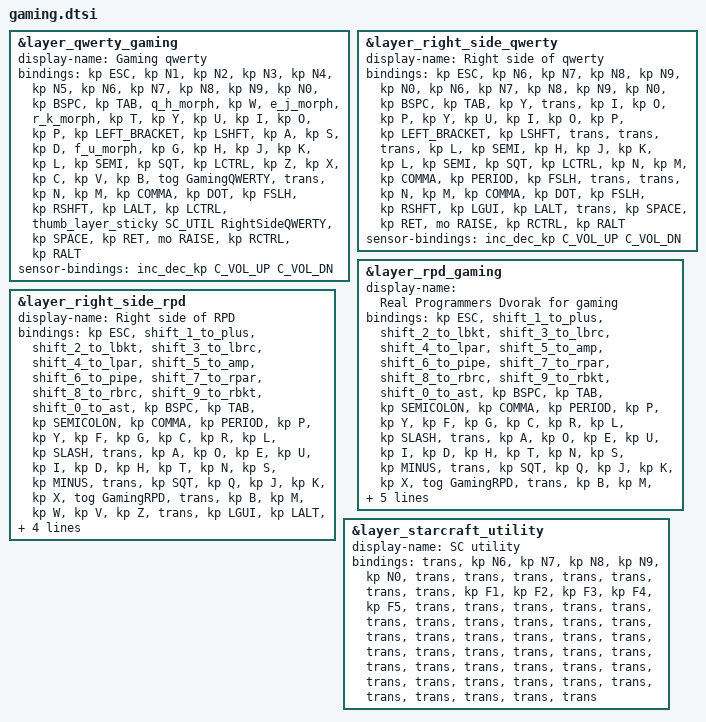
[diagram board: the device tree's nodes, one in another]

        &layer_qwerty_gaming {
            display-name = "Gaming qwerty";
            bindings = <
//    ┌──────┬────────────┬───┬────────────┬────────────┬───────────────────────────────────────────┐                            ┌────────────┬──────┬──────┬───┬───┬──────┐
//    │ esc  │     1      │ 2 │     3      │     4      │                     5                     │                            │     6      │  7   │  8   │ 9 │ 0 │ bspc │
//    ├──────┼────────────┼───┼────────────┼────────────┼───────────────────────────────────────────┤                            ├────────────┼──────┼──────┼───┼───┼──────┤
//    │ tab  │ &q_h_morph │ W │ &e_j_morph │ &r_k_morph │                     T                     │                            │     Y      │  U   │  I   │ O │ P │  [   │
//    ├──────┼────────────┼───┼────────────┼────────────┼───────────────────────────────────────────┤                            ├────────────┼──────┼──────┼───┼───┼──────┤
//    │ lsft │     A      │ S │     D      │ &f_u_morph │                     G                     │                            │     H      │  J   │  K   │ L │ ; │  '   │
//    ├──────┼────────────┼───┼────────────┼────────────┼───────────────────────────────────────────┼──────────────────┐   ┌─────┼────────────┼──────┼──────┼───┼───┼──────┤
//    │ lctl │     Z      │ X │     C      │     V      │                     B                     │ tog GamingQWERTY │   │     │     N      │  M   │  ,   │ . │ / │ rsft │
//    └──────┴────────────┴───┼────────────┼────────────┼───────────────────────────────────────────┼──────────────────┤   ├─────┼────────────┼──────┼──────┼───┴───┴──────┘
//                            │    lgui    │    lalt    │ &thumb_layer_sticky LOWER RightSideQWERTY │       spc        │   │ ent │ mo raltISE │ rctl │ ralt │
//                            └────────────┴────────────┴───────────────────────────────────────────┴──────────────────┘   └─────┴────────────┴──────┴──────┘
  &kp ESC     &kp N1       &kp N2   &kp N3       &kp N4       &kp N5                                                                        &kp N6      &kp N7      &kp N8      &kp N9    &kp N0     &kp BSPC
  &kp TAB     &q_h_morph   &kp W    &e_j_morph   &r_k_morph   &kp T                                                                         &kp Y       &kp U       &kp I       &kp O     &kp P      &kp LEFT_BRACKET
  &kp LSHFT   &kp A        &kp S    &kp D        &f_u_morph   &kp G                                                                         &kp H       &kp J       &kp K       &kp L     &kp SEMI   &kp SQT
  &kp LCTRL   &kp Z        &kp X    &kp C        &kp V        &kp B                                       &tog GamingQWERTY       &trans    &kp N       &kp M       &kp COMMA   &kp DOT   &kp FSLH   &kp RSHFT
                                    &kp LALT     &kp LCTRL     &thumb_layer_sticky SC_UTIL RightSideQWERTY   &kp SPACE               &kp RET   &mo RAISE   &kp RCTRL   &kp RALT
            >;

            sensor-bindings = <&inc_dec_kp C_VOL_UP C_VOL_DN>;
      };

      // mirror this shit
        &layer_right_side_qwerty {
            display-name = "Right side of qwerty";
            bindings = <
//    ┌──────┬─────┬─────┬──────┬──────┬─────┐               ┌────────────┬──────┬──────┬───┬───┬──────┐
//    │ esc  │  6  │  7  │  8   │  9   │  0  │               │     6      │  7   │  8   │ 9 │ 0 │ bspc │
//    ├──────┼─────┼─────┼──────┼──────┼─────┤               ├────────────┼──────┼──────┼───┼───┼──────┤
//    │ tab  │  Y  │     │  I   │  O   │  P  │               │     Y      │  U   │  I   │ O │ P │  [   │
//    ├──────┼─────┼─────┼──────┼──────┼─────┤               ├────────────┼──────┼──────┼───┼───┼──────┤
//    │ lsft │     │     │      │  L   │  ;  │               │     H      │  J   │  K   │ L │ ; │  '   │
//    ├──────┼─────┼─────┼──────┼──────┼─────┼─────┐   ┌─────┼────────────┼──────┼──────┼───┼───┼──────┤
//    │ lctl │  N  │  M  │  ,   │  .   │  /  │     │   │     │     N      │  M   │  ,   │ . │ / │ rsft │
//    └──────┴─────┴─────┼──────┼──────┼─────┼─────┤   ├─────┼────────────┼──────┼──────┼───┴───┴──────┘
//                       │ lgui │ lalt │     │ spc │   │ ent │ mo raltISE │ rctl │ ralt │
//                       └──────┴──────┴─────┴─────┘   └─────┴────────────┴──────┴──────┘
  &kp ESC     &kp N6   &kp N7   &kp N8      &kp N9       &kp N0                               &kp N6      &kp N7      &kp N8      &kp N9    &kp N0     &kp BSPC
  &kp TAB     &kp Y    &trans   &kp I       &kp O        &kp P                                &kp Y       &kp U       &kp I       &kp O     &kp P      &kp LEFT_BRACKET
  &kp LSHFT   &trans   &trans   &trans      &kp L        &kp SEMI                             &kp H       &kp J       &kp K       &kp L     &kp SEMI   &kp SQT
  &kp LCTRL   &kp N    &kp M    &kp COMMA   &kp PERIOD   &kp FSLH   &trans          &trans    &kp N       &kp M       &kp COMMA   &kp DOT   &kp FSLH   &kp RSHFT
                                &kp LGUI    &kp LALT     &trans     &kp SPACE       &kp RET   &mo RAISE   &kp RCTRL   &kp RALT
            >;

            sensor-bindings = <&inc_dec_kp C_VOL_UP C_VOL_DN>;
      };


        &layer_rpd_gaming {
            display-name = "Real Programmers Dvorak for gaming";
            bindings = <
//    ┌─────┬──────────────────┬──────────────────┬──────────────────┬──────────────────┬────────────────────────────────────────┐                         ┌──────────────────┬──────────────────┬──────────────────┬──────────────────┬─────────────────┬──────┐
//    │ esc │ &shift_1_to_plus │ &shift_2_to_lbkt │ &shift_3_to_lbrc │ &shift_4_to_lpar │            &shift_5_to_amp             │                         │ &shift_6_to_pipe │ &shift_7_to_rpar │ &shift_8_to_rbrc │ &shift_9_to_rbkt │ &shift_0_to_ast │ bspc │
//    ├─────┼──────────────────┼──────────────────┼──────────────────┼──────────────────┼────────────────────────────────────────┤                         ├──────────────────┼──────────────────┼──────────────────┼──────────────────┼─────────────────┼──────┤
//    │ tab │        ;         │        ,         │        .         │        P         │                   Y                    │                         │        F         │        G         │        C         │        R         │        L        │  /   │
//    ├─────┼──────────────────┼──────────────────┼──────────────────┼──────────────────┼────────────────────────────────────────┤                         ├──────────────────┼──────────────────┼──────────────────┼──────────────────┼─────────────────┼──────┤
//    │     │        A         │        O         │        E         │        U         │                   I                    │                         │        D         │        H         │        T         │        N         │        S        │  -   │
//    ├─────┼──────────────────┼──────────────────┼──────────────────┼──────────────────┼────────────────────────────────────────┼───────────────┐   ┌─────┼──────────────────┼──────────────────┼──────────────────┼──────────────────┼─────────────────┼──────┤
//    │     │        '         │        Q         │        J         │        K         │                   X                    │ tog GamingRPD │   │     │        B         │        M         │        W         │        V         │        Z        │      │
//    └─────┴──────────────────┴──────────────────┼──────────────────┼──────────────────┼────────────────────────────────────────┼───────────────┤   ├─────┼──────────────────┼──────────────────┼──────────────────┼──────────────────┴─────────────────┴──────┘
//                                                │       lgui       │       lalt       │ &thumb_layer_sticky LOWER RightSideRPD │      spc      │   │ ent │    mo raltISE    │       rctl       │       ralt       │
//                                                └──────────────────┴──────────────────┴────────────────────────────────────────┴───────────────┘   └─────┴──────────────────┴──────────────────┴──────────────────┘
  &kp ESC   &shift_1_to_plus   &shift_2_to_lbkt   &shift_3_to_lbrc   &shift_4_to_lpar   &shift_5_to_amp                                                         &shift_6_to_pipe   &shift_7_to_rpar   &shift_8_to_rbrc   &shift_9_to_rbkt   &shift_0_to_ast   &kp BSPC
  &kp TAB   &kp SEMICOLON      &kp COMMA          &kp PERIOD         &kp P              &kp Y                                                                   &kp F              &kp G              &kp C              &kp R              &kp L             &kp SLASH
  &trans    &kp A              &kp O              &kp E              &kp U              &kp I                                                                   &kp D              &kp H              &kp T              &kp N              &kp S             &kp MINUS
  &trans    &kp SQT            &kp Q              &kp J              &kp K              &kp X                                    &tog GamingRPD       &trans    &kp B              &kp M              &kp W              &kp V              &kp Z             &trans
                                                  &kp LGUI           &kp LALT           &thumb_layer_sticky LOWER RightSideRPD   &kp SPACE            &kp RET   &mo RAISE          &kp RCTRL          &kp RALT
            >;

            sensor-bindings = <&inc_dec_kp C_VOL_UP C_VOL_DN>;
        };

        &layer_right_side_rpd {
            display-name = "Right side of RPD";
            bindings = <
//    ┌─────┬──────────────────┬──────────────────┬──────────────────┬──────────────────┬─────────────────────────────────────┐                         ┌──────────────────┬──────────────────┬──────────────────┬──────────────────┬─────────────────┬──────┐
//    │ esc │ &shift_1_to_plus │ &shift_2_to_lbkt │ &shift_3_to_lbrc │ &shift_4_to_lpar │           &shift_5_to_amp           │                         │ &shift_6_to_pipe │ &shift_7_to_rpar │ &shift_8_to_rbrc │ &shift_9_to_rbkt │ &shift_0_to_ast │ bspc │
//    ├─────┼──────────────────┼──────────────────┼──────────────────┼──────────────────┼─────────────────────────────────────┤                         ├──────────────────┼──────────────────┼──────────────────┼──────────────────┼─────────────────┼──────┤
//    │ tab │        ;         │        ,         │        .         │        P         │                  Y                  │                         │        F         │        G         │        C         │        R         │        L        │  /   │
//    ├─────┼──────────────────┼──────────────────┼──────────────────┼──────────────────┼─────────────────────────────────────┤                         ├──────────────────┼──────────────────┼──────────────────┼──────────────────┼─────────────────┼──────┤
//    │     │        A         │        O         │        E         │        U         │                  I                  │                         │        D         │        H         │        T         │        N         │        S        │  -   │
//    ├─────┼──────────────────┼──────────────────┼──────────────────┼──────────────────┼─────────────────────────────────────┼───────────────┐   ┌─────┼──────────────────┼──────────────────┼──────────────────┼──────────────────┼─────────────────┼──────┤
//    │     │        '         │        Q         │        J         │        K         │                  X                  │ tog GamingRPD │   │     │        B         │        M         │        W         │        V         │        Z        │      │
//    └─────┴──────────────────┴──────────────────┼──────────────────┼──────────────────┼─────────────────────────────────────┼───────────────┤   ├─────┼──────────────────┼──────────────────┼──────────────────┼──────────────────┴─────────────────┴──────┘
//                                                │       lgui       │       lalt       │ &thumb_layer_tog LOWER RightSideRPD │      spc      │   │ ent │    mo raltISE    │       rctl       │       ralt       │
//                                                └──────────────────┴──────────────────┴─────────────────────────────────────┴───────────────┘   └─────┴──────────────────┴──────────────────┴──────────────────┘
  &kp ESC   &shift_1_to_plus   &shift_2_to_lbkt   &shift_3_to_lbrc   &shift_4_to_lpar   &shift_5_to_amp                                                      &shift_6_to_pipe   &shift_7_to_rpar   &shift_8_to_rbrc   &shift_9_to_rbkt   &shift_0_to_ast   &kp BSPC
  &kp TAB   &kp SEMICOLON      &kp COMMA          &kp PERIOD         &kp P              &kp Y                                                                &kp F              &kp G              &kp C              &kp R              &kp L             &kp SLASH
  &trans    &kp A              &kp O              &kp E              &kp U              &kp I                                                                &kp D              &kp H              &kp T              &kp N              &kp S             &kp MINUS
  &trans    &kp SQT            &kp Q              &kp J              &kp K              &kp X                                 &tog GamingRPD       &trans    &kp B              &kp M              &kp W              &kp V              &kp Z             &trans
                                                  &kp LGUI           &kp LALT           &thumb_layer_tog LOWER RightSideRPD   &kp SPACE            &kp RET   &mo RAISE          &kp RCTRL          &kp RALT
            >;

            sensor-bindings = <&inc_dec_kp C_VOL_UP C_VOL_DN>;
        };


        &layer_starcraft_utility {
            display-name = "SC utility";
            bindings = <
                &trans   &kp N6   &kp N7   &kp N8   &kp N9   &kp N0               &trans   &trans   &trans   &trans   &trans   &trans
                &trans   &kp F1   &kp F2   &kp F3   &kp F4   &kp F5               &trans   &trans   &trans   &trans   &trans   &trans
                &trans   &trans   &trans   &trans   &trans   &trans               &trans   &trans   &trans   &trans   &trans   &trans
                &trans   &trans   &trans   &trans   &trans   &trans   &trans      &trans   &trans   &trans   &trans   &trans   &trans   &trans
                                          &trans   &trans   &trans   &trans      &trans   &trans   &trans   &trans
            >;
        };
